# M2Sxxx register map
Vendor: Microsemi; Series: SmartFusion2; File version: 2.0.32
CPU: CM3 r2p1, little endian, MPU, no FPU, 4 interrupt priority bits
Registers are 32-bit, read-write, no defined reset value unless marked. A register's access mark holds for its fields unless they carry their own. Offsets are from the block's base; [hi:lo] are bit positions; {n}, {i} and the like mark numbered series.

## COMBLK — No description provided for this peripheral
Base 0x40016000
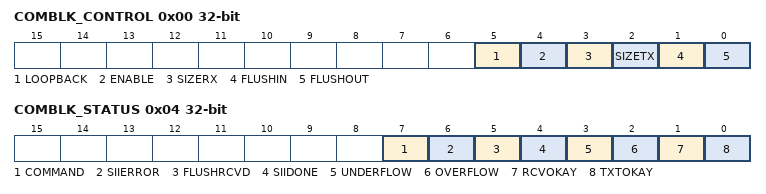
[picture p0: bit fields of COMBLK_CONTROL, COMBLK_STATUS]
0x00 COMBLK_CONTROL — No description provided for this register
  [5] LOOPBACK — No description provided for this field
  [4] ENABLE — No description provided for this field
  [3] SIZERX — No description provided for this field
  [2] SIZETX — No description provided for this field
  [1] FLUSHIN — No description provided for this field
  [0] FLUSHOUT — No description provided for this field
0x04 COMBLK_STATUS — No description provided for this register
  [7] COMMAND — No description provided for this field
  [6] SIIERROR — No description provided for this field
  [5] FLUSHRCVD — No description provided for this field
  [4] SIIDONE — No description provided for this field
  [3] UNDERFLOW — No description provided for this field
  [2] OVERFLOW — No description provided for this field
  [1] RCVOKAY — No description provided for this field
  [0] TXTOKAY — No description provided for this field
0x08 INTENABLE — No description provided for this register
  [7:0] ENABLE — No description provided for this field
0x10 Data8 — No description provided for this register
  [7:0] DATA8 — No description provided for this field
0x14 Data32 — No description provided for this register
  [31:0] DATA32 — No description provided for this field
0x18 FRAME_START8 — No description provided for this register
  [31:0] Frame_Start8 — No description provided for this field
0x1C FRAME_START32 — No description provided for this register
  [31:0] Frame_Start32 — No description provided for this field

## AHB_to_eNVM_0 — No description provided for this peripheral
Base 0x60080000
{0x0+4i} ENVM0_ASSEMBLY_BUFFER_{i} (i=0..31) — No description provided for this register
  [31:0] RD_DATA_ASSEM_BUFF_{i} ro — No description provided for this field
{0x80+4i} ENVM0_WD_BUFFER_{i} (i=0..31) — No description provided for this register
  [31:0] WR_DATA_BUFF_{i} — No description provided for this field
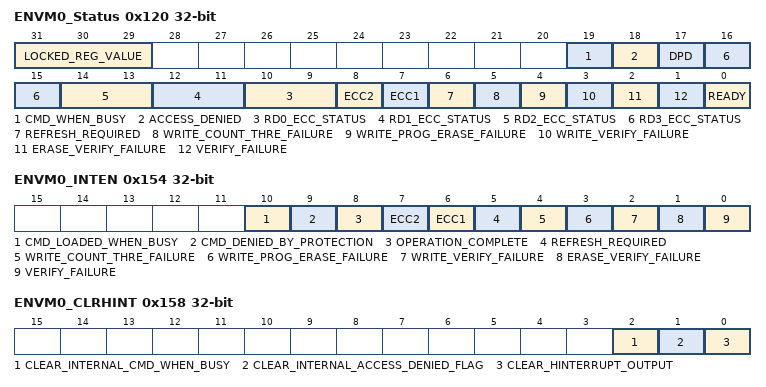
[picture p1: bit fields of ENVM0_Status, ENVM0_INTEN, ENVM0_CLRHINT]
0x120 ENVM0_Status — No description provided for this register
  [31:29] LOCKED_REG_VALUE ro — No description provided for this field
  [19] CMD_WHEN_BUSY ro — No description provided for this field
  [18] ACCESS_DENIED ro — No description provided for this field
  [17] DPD ro — No description provided for this field
  [2n+10:2n+9] RD{n}_ECC_STATUS ro (n=0..3) — No description provided for this field
  [8] ECC2 ro — No description provided for this field
  [7] ECC1 ro — No description provided for this field
  [6] REFRESH_REQUIRED ro — No description provided for this field
  [5] WRITE_COUNT_THRE_FAILURE ro — No description provided for this field
  [4] WRITE_PROG_ERASE_FAILURE ro — No description provided for this field
  [3] WRITE_VERIFY_FAILURE ro — No description provided for this field
  [2] ERASE_VERIFY_FAILURE ro — No description provided for this field
  [1] VERIFY_FAILURE ro — No description provided for this field
  [0] READY ro — No description provided for this field
0x128 ENVM0_PAGE_STATUS — No description provided for this register
  [0] STATUS — No description provided for this field
0x12C ENVM0_FREQRNG — No description provided for this register
  [3:0] FREQRNG ro — No description provided for this field
0x130 ENVM0_DPD — No description provided for this register
  [0] DPD ro — No description provided for this field
0x134 ENVM0_ENB_CACHE — No description provided for this register
  [0] NV_CE — No description provided for this field
0x140 ENVM0_PAGE_LOCK_SET — No description provided for this register
  [0] PAGELOCKBIT — No description provided for this field
0x144 ENVM0_DWSIZE — No description provided for this register
  [3:0] DWSIZE — No description provided for this field
0x148 ENVM0_CMD — No description provided for this register
  [31:0] CMD wo — No description provided for this field
0x154 ENVM0_INTEN — No description provided for this register
  [10] CMD_LOADED_WHEN_BUSY — No description provided for this field
  [9] CMD_DENIED_BY_PROTECTION — No description provided for this field
  [8] OPERATION_COMPLETE — No description provided for this field
  [7] ECC2 — No description provided for this field
  [6] ECC1 — No description provided for this field
  [5] REFRESH_REQUIRED — No description provided for this field
  [4] WRITE_COUNT_THRE_FAILURE — No description provided for this field
  [3] WRITE_PROG_ERASE_FAILURE — No description provided for this field
  [2] WRITE_VERIFY_FAILURE — No description provided for this field
  [1] ERASE_VERIFY_FAILURE — No description provided for this field
  [0] VERIFY_FAILURE — No description provided for this field
0x158 ENVM0_CLRHINT — No description provided for this register
  [2] CLEAR_INTERNAL_CMD_WHEN_BUSY — No description provided for this field
  [1] CLEAR_INTERNAL_ACCESS_DENIED_FLAG — No description provided for this field
  [0] CLEAR_HINTERRUPT_OUTPUT — No description provided for this field
0x1FC ENVM0_REQACCESS — No description provided for this register
  [2:0] RRA — No description provided for this field
